# STM32U5xx register map
File version: 1.3
Registers are 32-bit, read-write, reset 0x0 unless marked. A register's access mark holds for its fields unless they carry their own. Offsets are from the block's base; [hi:lo] are bit positions; {n}, {i} and the like mark numbered series.

## PWR — Power control
Base 0x46020800
Same registers: SEC_PWR 0x56020800
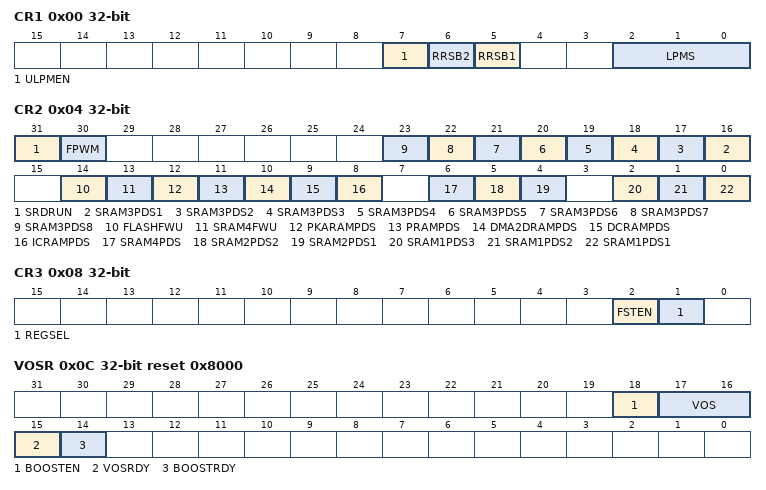
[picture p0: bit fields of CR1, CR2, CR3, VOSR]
0x00 CR1 — Power control register 1
  [7] ULPMEN — BOR ultra-low power mode
  [6] RRSB2 — SRAM2 page 2 retention in Stop3 and Standby modes
  [5] RRSB1 — SRAM2 page 1 retention in Stop3 and Standby modes
  [2:0] LPMS — Low-power mode selection
0x04 CR2 — Power control register 2
  [31] SRDRUN — SmartRun domain in Run mode
  [30] FPWM — SMPS PWM mode
  [n+15] SRAM3PDS{n} (n=1..8) — SRAM3 page {n} (64 Kbytes) power-down in Stop modes
  [14] FLASHFWU — Flash memory fast wakeup from Stop 0 and Stop 1 modes
  [13] SRAM4FWU — SRAM4 fast wakeup from Stop 0, Stop 1 and Stop 2 modes
  [12] PKARAMPDS — PKA32 SRAM power-down in Stop modes
  [11] PRAMPDS — FMAC, FDCAN and USB peripherals SRAM power-down in Stop modes
  [10] DMA2DRAMPDS — DMA2D SRAM power-down in Stop modes
  [9] DCRAMPDS — DCACHE SRAM power-down in Stop modes
  [8] ICRAMPDS — ICACHE SRAM power-down in Stop modes
  [6] SRAM4PDS — SRAM4 power-down in Stop modes
  [5] SRAM2PDS2 — SRAM2 page 2 (56 Kbytes) power-down in Stop modes
  [4] SRAM2PDS1 — SRAM2 page 1 (8 Kbytes) power-down in Stop modes
  [2] SRAM1PDS3 — SRAM1 page 3 (64 Kbytes) power-down in Stop modes
  [1] SRAM1PDS2 — SRAM1 page 2 (64 Kbytes) power-down in Stop modes
  [0] SRAM1PDS1 — SRAM1 page 1 (64 Kbytes) power-down in Stop modes
0x08 CR3 — Power control register 3
  [2] FSTEN — Fast soft start
  [1] REGSEL — Regulator selection
0x0C VOSR access per field reset 0x8000 — Power voltage scaling register
  [18] BOOSTEN rw — EPOD booster enable
  [17:16] VOS rw — Voltage scaling range selection
  [15] VOSRDY ro — Ready bit for VCORE voltage scaling output selection
  [14] BOOSTRDY ro — EPOD booster ready
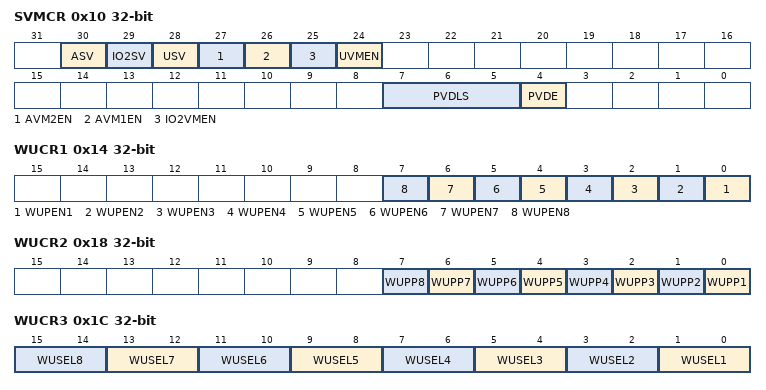
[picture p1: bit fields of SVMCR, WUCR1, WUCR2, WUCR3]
0x10 SVMCR — Power supply voltage monitoring control register
  [30] ASV — VDDA independent analog supply valid
  [29] IO2SV — VDDIO2 independent I/Os supply valid
  [28] USV — VDDUSB independent USB supply valid
  [27] AVM2EN — VDDA independent analog supply voltage monitor 2 enable
  [26] AVM1EN — VDDA independent analog supply voltage monitor 1 enable
  [25] IO2VMEN — VDDIO2 independent I/Os voltage monitor enable
  [24] UVMEN — VDDUSB independent USB voltage monitor enable
  [7:5] PVDLS — Power voltage detector level selection
  [4] PVDE — Power voltage detector enable
0x14 WUCR1 — Power wakeup control register 1
  [n-1] WUPEN{n} (n=1..8) — Wakeup pin WKUP{n} enable
0x18 WUCR2 — Power wakeup control register 2
  [n-1] WUPP{n} (n=1..8) — Wakeup pin WKUP{n} polarity
0x1C WUCR3 — Power wakeup control register 3
  [2n-1:2n-2] WUSEL{n} (n=1..8)
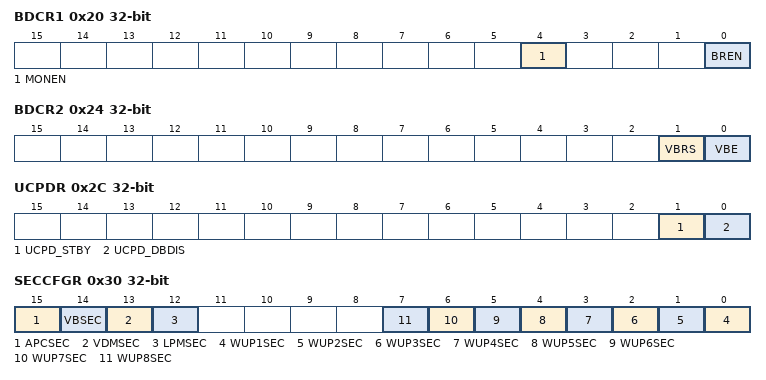
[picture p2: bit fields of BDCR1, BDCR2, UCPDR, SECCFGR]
0x20 BDCR1 — Power Backup domain control register 1
  [4] MONEN — Backup domain voltage and temperature monitoring enable
  [0] BREN — Backup RAM retention in Standby and VBAT modes
0x24 BDCR2 — Power Backup domain control register 2
  [1] VBRS — VBAT charging resistor selection
  [0] VBE — VBAT charging enable
0x28 DBPR — Power disable Backup domain register
  [0] DBP — Disable Backup domain write protection
0x2C UCPDR — USB Type_C and Power Delivery register
  [1] UCPD_STBY — UCPD Standby mode
  [0] UCPD_DBDIS — UCPD dead battery disable
0x30 SECCFGR — Power security configuration register
  [15] APCSEC
  [14] VBSEC — Backup domain secure protection
  [13] VDMSEC — Voltage detection and monitoring secure protection
  [12] LPMSEC — Low-power modes secure protection
  [n-1] WUP{n}SEC (n=1..8)
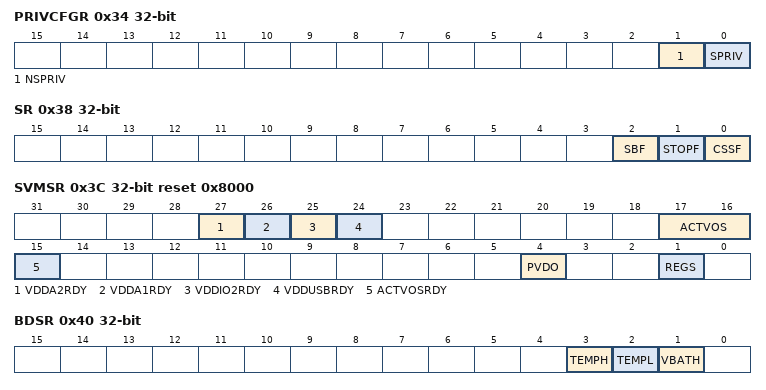
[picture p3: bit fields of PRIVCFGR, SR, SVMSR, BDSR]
0x34 PRIVCFGR — Power privilege control register
  [1] NSPRIV — PWR non-secure functions privilege configuration
  [0] SPRIV — PWR secure functions privilege configuration
0x38 SR access per field — Power status register
  [2] SBF ro — Standby flag
  [1] STOPF ro — Stop flag
  [0] CSSF wo — Clear Stop and Standby/Shutdown flags
0x3C SVMSR ro reset 0x8000 — Power supply voltage monitoring status register
  [27] VDDA2RDY, [26] VDDA1RDY, [25] VDDIO2RDY, [24] VDDUSBRDY, [17:16] ACTVOS, [15] ACTVOSRDY, [4] PVDO, [1] REGS
0x40 BDSR ro — Power Backup domain status register
  [3] TEMPH — Temperature level monitoring versus high threshold
  [2] TEMPL — Temperature level monitoring versus low threshold
  [1] VBATH — Backup domain voltage level monitoring versus high threshold
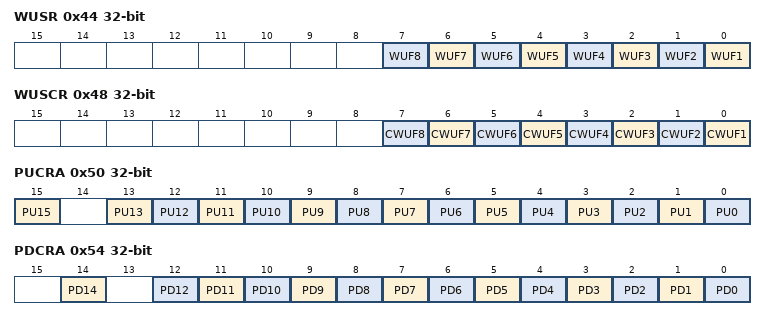
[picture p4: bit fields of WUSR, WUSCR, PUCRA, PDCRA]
0x44 WUSR ro — Power wakeup status register
  [n-1] WUF{n} (n=1..8) — Wakeup flag {n}
0x48 WUSCR wo — Power wakeup status clear register
  [n-1] CWUF{n} (n=1..8) — Wakeup flag {n}
0x4C APCR — Power apply pull configuration register
  [0] APC — Apply pull up and pull down configuration
0x50 PUCRA — Power port A pull up control register
  [15] PU15, [n] PU{n} (n=0..13)
0x54 PDCRA — Power port A pull down control register
  [14] PD14, [n] PD{n} (n=0..12)
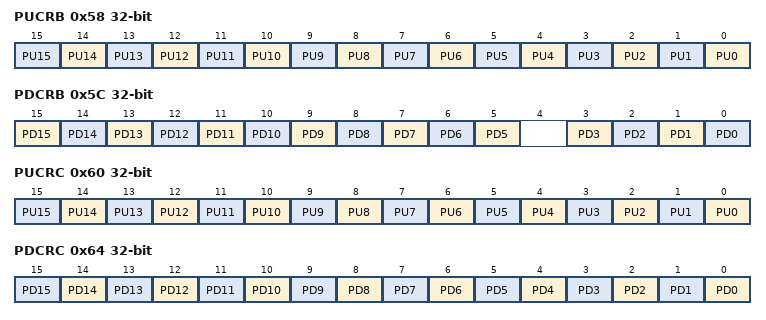
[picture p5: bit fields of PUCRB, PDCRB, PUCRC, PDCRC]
0x58 PUCRB — Power port B pull up control register
  [n] PU{n} (n=0..15)
0x5C PDCRB — Power port B pull down control register
  [n] PD{n} (n=5..15), [n] PD{n} (n=0..3)
0x60 PUCRC — Power port C pull up control register
  [n] PU{n} (n=0..15)
0x64 PDCRC — Power port C pull down control register
  [n] PD{n} (n=0..15)
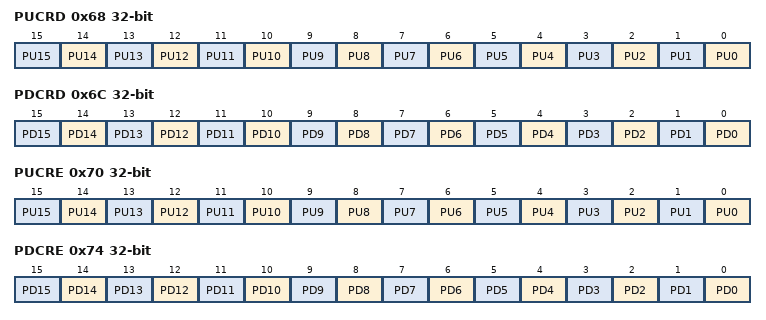
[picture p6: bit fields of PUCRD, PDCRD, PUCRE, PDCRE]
0x68 PUCRD — Power port D pull up control register
  [n] PU{n} (n=0..15)
0x6C PDCRD — Power port D pull down control register
  [n] PD{n} (n=0..15)
0x70 PUCRE — Power port E pull up control register
  [n] PU{n} (n=0..15)
0x74 PDCRE — Power port E pull down control register
  [n] PD{n} (n=0..15)
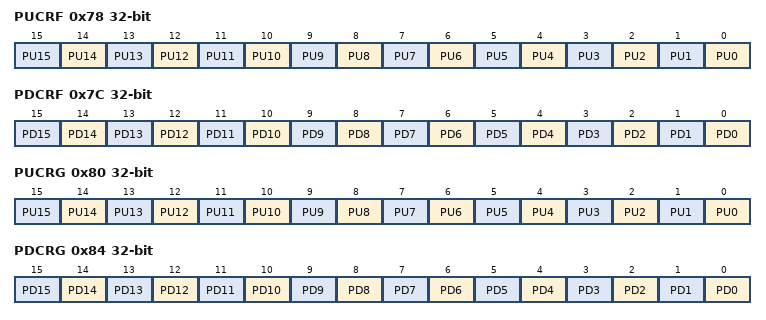
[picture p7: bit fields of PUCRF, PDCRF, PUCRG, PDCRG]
0x78 PUCRF — Power port F pull up control register
  [n] PU{n} (n=0..15)
0x7C PDCRF — Power port F pull down control register
  [n] PD{n} (n=0..15)
0x80 PUCRG — Power port G pull up control register
  [n] PU{n} (n=0..15)
0x84 PDCRG — Power port G pull down control register
  [n] PD{n} (n=0..15)
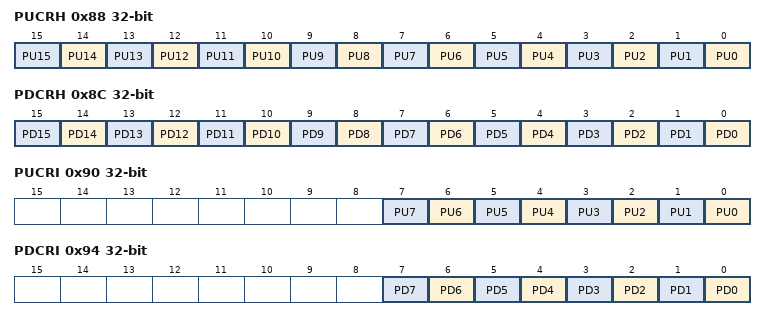
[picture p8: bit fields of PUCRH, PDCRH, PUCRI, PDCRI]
0x88 PUCRH — Power port H pull up control register
  [n] PU{n} (n=0..15)
0x8C PDCRH — Power port H pull down control register
  [n] PD{n} (n=0..15)
0x90 PUCRI — Power port I pull up control register
  [n] PU{n} (n=0..7)
0x94 PDCRI — Power port I pull down control register
  [n] PD{n} (n=0..7)
